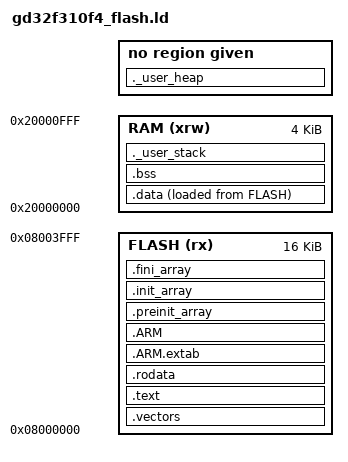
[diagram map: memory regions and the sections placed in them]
/* Entry Point */
ENTRY(Reset_Handler)

/* Highest address of the user mode stack */
_sp = 0x20001000;    /* end of RAM */
/* Generate a link error if heap and stack don't fit into RAM */
_Min_Heap_Size = 0x200;  /* required amount of heap  */
_Min_Stack_Size = 0x400; /* required amount of stack */

/* Specify the memory areas */
MEMORY
{
RAM (xrw)      : ORIGIN = 0x20000000, LENGTH = 4K
FLASH (rx)     : ORIGIN = 0x08000000, LENGTH = 16K
}

/* Define output sections */
SECTIONS
{  
/* ISR vectors */
  .vectors :
  {
    . = ALIGN(4);
    KEEP(*(.vectors))
    . = ALIGN(4);
  } >FLASH

  /* The program code and other data goes into FLASH */
  .text :
  {
    . = ALIGN(4);
    *(.text)
    *(.text*)
    *(.glue_7) 
    *(.glue_7t)
    *(.eh_frame)

    KEEP (*(.init))
    KEEP (*(.fini))

    . = ALIGN(4);
    _etext = .;        /* define a global symbols at end of code */
  } >FLASH

  .rodata :
  {
    . = ALIGN(4);
    *(.rodata)
    *(.rodata*)
    . = ALIGN(4);
  } >FLASH

   .ARM.extab :
  { 
    *(.ARM.extab* .gnu.linkonce.armextab.*) 
  } >FLASH
  
  .ARM :
  {
    __exidx_start = .;
    *(.ARM.exidx*)
    __exidx_end = .;
  } >FLASH

  .preinit_array :
  {
    PROVIDE_HIDDEN (__preinit_array_start = .);
    KEEP (*(.preinit_array*))
    PROVIDE_HIDDEN (__preinit_array_end = .);
  } >FLASH
  .init_array :
  {
    PROVIDE_HIDDEN (__init_array_start = .);
    KEEP (*(SORT(.init_array.*)))
    KEEP (*(.init_array*))
    PROVIDE_HIDDEN (__init_array_end = .);
  } >FLASH
  .fini_array :
  {
    PROVIDE_HIDDEN (__fini_array_start = .);
    KEEP (*(.fini_array*))
    KEEP (*(SORT(.fini_array.*)))
    PROVIDE_HIDDEN (__fini_array_end = .);
  } >FLASH

  /* provide some necessary symbols for startup file to initialize data */
  _sidata = LOADADDR(.data);

  /* Initialized data sections goes into RAM, load LMA copy after code */
  .data :
  {
    . = ALIGN(4);
    _sdata = .;        /* create a global symbol at data start */
    *(.data)
    *(.data*)
    . = ALIGN(4);
    _edata = .;        /* define a global symbol at data end */
  } >RAM AT> FLASH

  /* Uninitialized data section */
  . = ALIGN(4);
  .bss :
  {
    /* This is used by the startup in order to initialize the .bss secion */
    _sbss = .;
    __bss_start__ = _sbss;
    *(.bss)
    *(.bss*)
    *(COMMON)
  
    . = ALIGN(4);
    _ebss = .;         /* define a global symbol at bss end */
    __bss_end__ = _ebss;
  } >RAM

  /* User_heap_stack section, used to check that there is enough RAM left */
  ._user_stack :
  {
    . = ALIGN(8);
    . = . + _Min_Stack_Size;
    . = ALIGN(8);
  } >RAM

  ._user_heap :
  {
    . = ALIGN(4);
    PROVIDE ( end = . );
    PROVIDE ( _end = . );
    . = ALIGN(4);
  } >EXRAM

  

  /* Remove information from the standard libraries */
  /DISCARD/ :
  {
    libc.a ( * )
    libm.a ( * )
    libgcc.a ( * )
  }

  .ARM.attributes 0 : { *(.ARM.attributes) }
}


